# MPU_PRM register map
Vendor: Texas Instruments
Peripheral module from a debugger description file (folder omap5430_ES2_PUBLIC).
Registers are 32-bit, access not given, reset 0x3C0607 unless marked. A register's access mark holds for its fields unless they carry their own. Offsets are as the file gives them; lines under a group give offsets from that group; [hi:lo] are bit positions; {n}, {i} and the like mark numbered series; 'fields as' and 'values as' point back to an identical list; <NAME> marks a mode.

## MPU_PRM
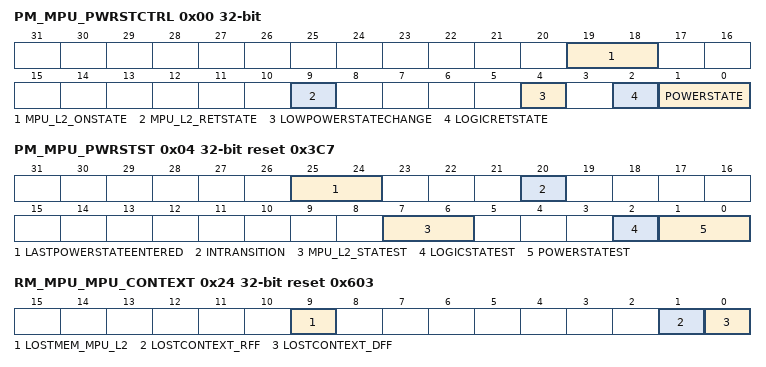
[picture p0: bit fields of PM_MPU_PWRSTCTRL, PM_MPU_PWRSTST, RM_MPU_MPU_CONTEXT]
0x00 PM_MPU_PWRSTCTRL access per field — This register controls the MPU domain power state to reach upon a domain sleep transition. If the value programmed in this register correspond to a lower power state than the one programmed in MPU SS for CPU0 and/or CPU1, then value of this register is overwritten in PRCM logic to limit the power state to enter. Even if value of this register is overwitten in PRCM logic, value of this register remains unchanged.
  [19:18] MPU_L2_ONSTATE ro — MPU_L2 memory state when domain is ON.
    3=Mem_on (Memory bank is on when the domain is ON.)
  [9] MPU_L2_RETSTATE rw — MPU_L2 memory state when domain is RETENTION.
    0=mem_off (Memory bank is off when the domain is in the RETENTION state.); 1=mem_ret (Memory bank is retained when domain is in RETENTION state.)
  [4] LOWPOWERSTATECHANGE ro — Power state change request when domain has already performed a sleep transition. Allows going into deeper low power state without waking up the power domain.
    0=DIS (Do not request a low power state change.)
  [2] LOGICRETSTATE rw — Logic state when power domain is RETENTION
    0=logic_off (Only retention registers are retained and remaing logic is off when the domain is in RETENTION state.); 1=logic_ret (Whole logic is retained when domain is in RETENTION state.)
  [1:0] POWERSTATE rw — Power state control.
    1=RET (RETENTION state); 2=INACT (INACTIVE state); 3=ON (ON State)
0x04 PM_MPU_PWRSTST reset 0x3C7 — This register provides a status on the MPU domain current power state. [warm reset insensitive]
  [25:24] LASTPOWERSTATEENTERED — Last low power state entered. Set to 0x3 upon write of the same only. This register is intended for debug purpose only. (access RW W1toSet)
    3=ON (Power domain was previously ON-ACTIVE); 2=INACTIVE (Power domain was previously ON-INACTIVE); 1=RET (Power domain was previously in RETENTION); 0=OFF (Reserved)
  [20] INTRANSITION ro — Domain transition status
    0=No (No on-going transition on power domain); 1=Ongoing (Power domain transition is in progress.)
  [7:6] MPU_L2_STATEST ro — MPU_L2 memory state status
    0=Mem_off (Reserved); 1=Mem_ret (Memory is RETENTION); 3=Mem_on (Memory is ON)
  [2] LOGICSTATEST ro — Logic state status
    0=OFF (Logic in domain is OFF); 1=ON (Logic in domain is ON)
  [1:0] POWERSTATEST ro — Current power state status
    0=OFF (Reserved); 1=RET (Power domain is in RETENTION); 2=INACTIVE (Power domain is ON-INACTIVE); 3=ON (Power domain is ON-ACTIVE)
0x24 RM_MPU_MPU_CONTEXT reset 0x603 — This register contains dedicated MPU context statuses. [warm reset insensitive]
  [all] fields
    0=Maintained (Context has been maintained); 1=Lost (Context has been lost)
  [9] LOSTMEM_MPU_L2 — Specify if memory-based context in MPU_L2 memory bank has been lost due to a previous power transition or other reset source. (access RW W1toClr)
  [1] LOSTCONTEXT_RFF — Specify if RFF-based context has been lost due to a previous power transition or other reset source. (set upon assertion of MPU_MA_PWRON_RET_RST signal) (access RW W1toClr)
  [0] LOSTCONTEXT_DFF — Specify if DFF-based context has been lost due to a previous power transition or other reset source. (set upon assertion of MPU_RST signal) (access RW W1toClr)
